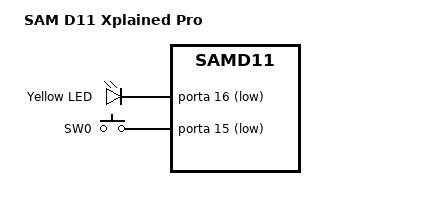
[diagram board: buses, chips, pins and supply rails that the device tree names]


/dts-v1/;
#include <freq.h>
#include <atmel/samd1x.dtsi>
#include <atmel/samx1xx14.dtsi>
#include "samd11_xpro-pinctrl.dtsi"
#include <zephyr/dt-bindings/input/input-event-codes.h>

/ {
	model = "SAM D11 Xplained Pro";
	compatible = "samd11,xpro", "atmel,samd11d14am", "atmel,samd11";

	chosen {
		zephyr,sram = &sram0;
		zephyr,flash = &flash0;
	};

	/* These aliases are provided for compatibility with samples */
	aliases {
		led0 = &led0;
		// pwm-led0 = &pwm_led0;
		// sw0 = &user_button;
		// i2c-0 = &sercom2;
	};

	leds {
		compatible = "gpio-leds";
		led0: led_0 {
			gpios = <&porta 16 GPIO_ACTIVE_LOW>;
			label = "Yellow LED";
		};
	};

	// pwmleds {
	// 	compatible = "pwm-leds";
	// 	pwm_led0: pwm_led_0 {
	// 		pwms = <&tcc0 0 PWM_MSEC(20)>;
	// 	};
	// };

	buttons {
		compatible = "gpio-keys";
		user_button: button_0 {
			gpios = <&porta 15 (GPIO_PULL_UP | GPIO_ACTIVE_LOW)>;
			label = "SW0";
			zephyr,code = <INPUT_KEY_0>;
		};
	};
};

&cpu0 {
	clock-frequency = <DT_FREQ_M(48)>;
};

// &sercom0 {
// 	status = "okay";
// 	compatible = "atmel,sam0-uart";
// 	current-speed = <9600>;
// 	rxpo = <3>;
// 	txpo = <1>;
	
// 	pinctrl-0 = <&sercom0_uart_default>;
// 	pinctrl-names = "default";
// };

// &sercom1 {
// 	status = "okay";
// 	compatible = "atmel,sam0-uart";
// 	current-speed = <115200>;
// 	rxpo = <3>;
// 	txpo = <0>;

// 	pinctrl-0 = <&sercom1_uart_default>;
// 	pinctrl-names = "default";
// };

// &sercom2 {
// 	status = "okay";
// 	compatible = "atmel,sam0-i2c";
// 	clock-frequency = <I2C_BITRATE_FAST>;
// 	#address-cells = <1>;
// 	#size-cells = <0>;

// 	pinctrl-0 = <&sercom2_i2c_default>;
// 	pinctrl-names = "default";
// };

